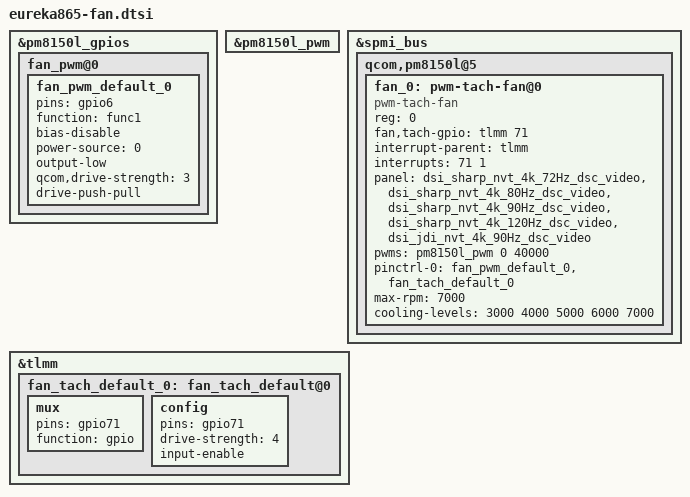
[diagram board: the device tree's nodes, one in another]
// SPDX-License-Identifier: GPL-2.0

&pm8150l_gpios {
	fan_pwm@0 {
		fan_pwm_default_0: fan_pwm_default_0 {
			pins = "gpio6";
			function = "func1";
			bias-disable;
			power-source = <0>;
			output-low;
			qcom,drive-strength = <3>;
			drive-push-pull;
			status = "okay";
		};
	};
};

&pm8150l_pwm {
	status = "okay";
};

&spmi_bus {
	qcom,pm8150l@5 {
		fan_0: pwm-tach-fan@0 {
			reg = <0>;
			compatible = "pwm-tach-fan";
			fan,tach-gpio = <&tlmm 71 0x0>;
			interrupt-parent = <&tlmm>;
			interrupts = <71 1>;
			interrupt-names = "fan_irq";
			panel = <&dsi_sharp_nvt_4k_72Hz_dsc_video
					&dsi_sharp_nvt_4k_80Hz_dsc_video
					&dsi_sharp_nvt_4k_90Hz_dsc_video
					&dsi_sharp_nvt_4k_120Hz_dsc_video
					&dsi_jdi_nvt_4k_90Hz_dsc_video>;
			/*25KHz -> 40000ns*/
			pwms = <&pm8150l_pwm 0 40000>;
			pinctrl-names = "default";
			pinctrl-0 = <&fan_pwm_default_0
				&fan_tach_default_0>;
			status = "okay";
			max-rpm = <7000>;
			#cooling-cells = <2>;
			/* TODO(D37872176): revert D37872176 when we setup the fan control */
			cooling-levels = <3000 4000 5000 6000 7000>;
		};
	};
};

&tlmm {
	fan_tach_default_0: fan_tach_default@0 {
		mux {
			pins = "gpio71";
			function = "gpio";
		};
		config {
			pins = "gpio71";
			drive-strength = <4>;
			input-enable;
		};
	};
};
